AUTOSAR XML (schema 4-3-0)
package /App_NvM
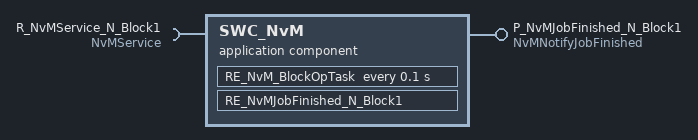
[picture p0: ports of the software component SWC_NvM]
  application sw component type SWC_NvM
    provide port P_NvMJobFinished_N_Block1: server-com-spec{operation=JobFinished, queue-length=1}, provided-interface=NvMNotifyJobFinished
    require port R_NvMService_N_Block1: required-com-specs=[GetErrorStatus, ReadBlock, WriteBlock, RestoreBlockDefaults, CancelJobs, EraseNvBlock, InvalidateNvBlock], required-interface=NvMService
    behavior InternalBehavior
      timing event TE_NvM_BlockOpTask: start-on-event=RE_NvM_BlockOpTask, period=0.1
      operation invoked event OIE_NvMJobFinished_N_Block1: start-on-event=RE_NvMJobFinished_N_Block1, operation=P_NvMJobFinished_N_Block1.JobFinished
      runnable RE_NvMJobFinished_N_Block1: symbol=NvMJobFinished_N_Block1
      runnable RE_NvM_BlockOpTask: symbol=NvM_BlockOpTask
        7 x sync call:
          SSCP_RE_NvM_BlockOpTask_R_NvMService_N_Block1_CancelJobs: operation=R_NvMService_N_Block1.CancelJobs
          SSCP_RE_NvM_BlockOpTask_R_NvMService_N_Block1_EraseNvBlock: operation=R_NvMService_N_Block1.EraseNvBlock
          SSCP_RE_NvM_BlockOpTask_R_NvMService_N_Block1_GetErrorStatus: operation=R_NvMService_N_Block1.GetErrorStatus
          SSCP_RE_NvM_BlockOpTask_R_NvMService_N_Block1_InvalidateNvBlock: operation=R_NvMService_N_Block1.InvalidateNvBlock
          SSCP_RE_NvM_BlockOpTask_R_NvMService_N_Block1_ReadBlock: operation=R_NvMService_N_Block1.ReadBlock
          SSCP_RE_NvM_BlockOpTask_R_NvMService_N_Block1_RestoreBlockDefaults: operation=R_NvMService_N_Block1.RestoreBlockDefaults
          SSCP_RE_NvM_BlockOpTask_R_NvMService_N_Block1_WriteBlock: operation=R_NvMService_N_Block1.WriteBlock
